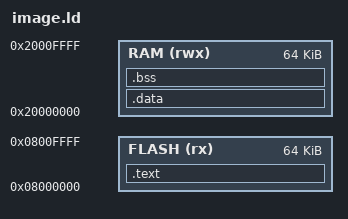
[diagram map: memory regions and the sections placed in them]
ENTRY(thumb1_vector_probe)
MEMORY {
    FLASH (rx) : ORIGIN = 0x08000000, LENGTH = 64K
    RAM (rwx) : ORIGIN = 0x20000000, LENGTH = 64K
}
SECTIONS {
    .text : { *(.text*) *(.rodata*) } > FLASH
    .data : { *(.data*) } > RAM
    .bss (NOLOAD) : { *(.bss*) *(COMMON) } > RAM
    /DISCARD/ : { *(.ARM.exidx*) *(.ARM.extab*) *(.comment*) }
}
